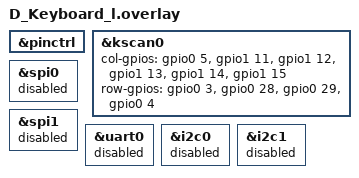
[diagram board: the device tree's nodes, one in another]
#include "D_Keyboard.dtsi"

&pinctrl {
    /delete-node/ spi0_default;
    /delete-node/ spi0_sleep;
};

&kscan0 {
    col-gpios
        = <&gpio0 5  GPIO_ACTIVE_HIGH>
        , <&gpio1 11 GPIO_ACTIVE_HIGH>
        , <&gpio1 12 GPIO_ACTIVE_HIGH>
        , <&gpio1 13 GPIO_ACTIVE_HIGH>
        , <&gpio1 14 GPIO_ACTIVE_HIGH>
        , <&gpio1 15 GPIO_ACTIVE_HIGH>
        ;

    row-gpios
        = <&gpio0 3  (GPIO_ACTIVE_HIGH | GPIO_PULL_DOWN)>
        , <&gpio0 28 (GPIO_ACTIVE_HIGH | GPIO_PULL_DOWN)>
        , <&gpio0 29 (GPIO_ACTIVE_HIGH | GPIO_PULL_DOWN)>
        , <&gpio0 4  (GPIO_ACTIVE_HIGH | GPIO_PULL_DOWN)>
        ;
};

&spi0 { status = "disabled"; };
&spi1 { status = "disabled"; };
&uart0 { status = "disabled"; };
&i2c0 { status = "disabled"; };
&i2c1 { status = "disabled"; };
